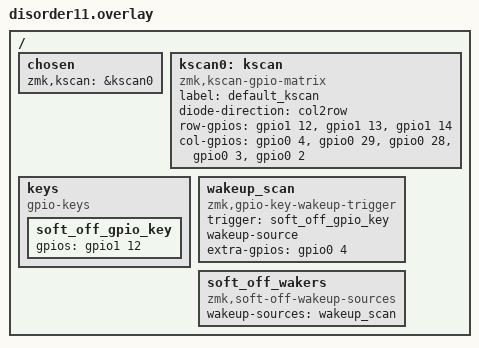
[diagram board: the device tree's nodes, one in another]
#include <zephyr/dt-bindings/dt-util.h>

#include <dt-bindings/zmk/matrix_transform.h>
#include <physical_layouts.dtsi>

#include "disorder11-transforms.dtsi"
#include "disorder11-layouts.dtsi"

/ {
    chosen {
        zmk,kscan = &kscan0;
    };

    kscan0: kscan {
        compatible = "zmk,kscan-gpio-matrix";
        label = "default_kscan";
        diode-direction = "col2row";

        row-gpios =  <&gpio1 12 (GPIO_ACTIVE_HIGH | GPIO_PULL_DOWN)>
                  ,  <&gpio1 13 (GPIO_ACTIVE_HIGH | GPIO_PULL_DOWN)>
                  ,  <&gpio1 14 (GPIO_ACTIVE_HIGH | GPIO_PULL_DOWN)>
                  ;

        col-gpios =  <&gpio0 4 GPIO_ACTIVE_HIGH>
                  ,  <&gpio0 29 GPIO_ACTIVE_HIGH>
                  ,  <&gpio0 28 GPIO_ACTIVE_HIGH>
                  ,  <&gpio0 3 GPIO_ACTIVE_HIGH>
                  ,  <&gpio0 2 GPIO_ACTIVE_HIGH>
                  ;
    };
};
/ {
    keys {
        compatible = "gpio-keys";
        soft_off_gpio_key: soft_off_gpio_key {
            gpios = <&gpio1 12 (GPIO_ACTIVE_HIGH | GPIO_PULL_DOWN)>;
        };
    };
};
/ {
    wakeup_scan: wakeup_scan {
        compatible = "zmk,gpio-key-wakeup-trigger";
        trigger = <&soft_off_gpio_key>;
        wakeup-source;
        extra-gpios = <&gpio0 4 GPIO_ACTIVE_HIGH>;
    };
};
/ {
    soft_off_wakers {
        compatible = "zmk,soft-off-wakeup-sources";
        wakeup-sources = <&wakeup_scan>;
    };
};


